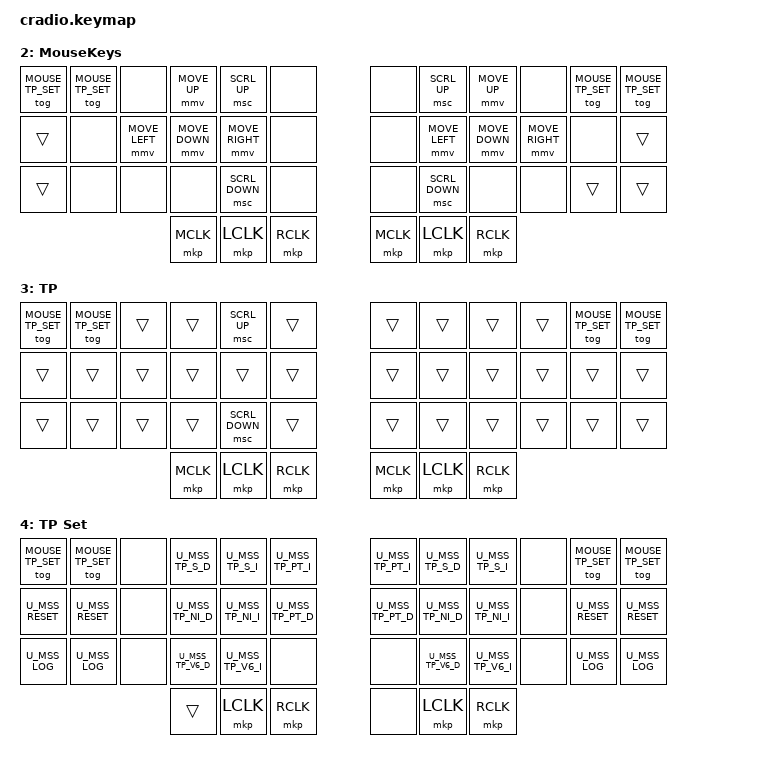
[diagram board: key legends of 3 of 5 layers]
// Copyright (c) 2022 The ZMK Contributors
// SPDX-License-Identifier: MIT

#include <behaviors.dtsi>
#include <dt-bindings/zmk/keys.h>
#include <dt-bindings/zmk/bt.h>

// Layer definitions (same as original PS/2 config)
#define BASE 0
#define LOWER 1
#define MOUSE_KEYS 2
#define MOUSE_TP 3
#define MOUSE_TP_SET 4

#define HAS_MOUSE_KEYS
#define HAS_MOUSE_TP

#ifdef HAS_MOUSE_KEYS
  #include <dt-bindings/zmk/mouse.h>
  #include <behaviors/mouse_keys.dtsi>
#endif

#ifdef HAS_MOUSE_TP
  #include <dt-bindings/zmk/mouse_settings.h>
  #include <behaviors/mouse_keys.dtsi>
  #include <behaviors/mouse_setting.dtsi>
  #include "include/mouse_tp.dtsi"
#endif

// Homery mods macro for cradio
#define HRML(k1,k2,k3,k4) &ht LSHFT k1 &ht LALT k2 &ht LCTRL k3 &ht LGUI k4
#define HRMR(k1,k2,k3,k4) &ht RGUI k1 &ht RCTRL k2 &ht RALT k3 &ht RSHFT k4

// Layer toggle helpers
#ifdef HAS_MOUSE_KEYS
  #define U_THUMB_INNER &mo MOUSE_KEYS
#else
  #define U_THUMB_INNER &none
#endif

#ifdef HAS_MOUSE_TP
  #define U_TOG_TP_SET &tog MOUSE_TP_SET
#else
  #define U_TOG_TP_SET &none
#endif

/ {
    behaviors {
        ht: hold_tap {
            compatible = "zmk,behavior-hold-tap";
            #binding-cells = <2>;
            flavor = "tap-preferred";
            tapping-term-ms = <220>;
            quick-tap-ms = <150>;
            require-prior-idle-ms = <100>;
            bindings = <&kp>, <&kp>;
        };
    };

    conditional_layers {
        compatible = "zmk,conditional-layers";
        tri_layer {
            if-layers = <1 2>;
            then-layer = <3>;
        };
    };

    keymap {
        compatible = "zmk,keymap";

        // Layer 0: Base
        default_layer {
            display-name = "Base";
            bindings = <
        //╭──────────┬──────────┬──────────┬──────────┬──────────╮   ╭──────────┬──────────┬──────────┬──────────┬──────────╮
        //│  Q       │  W       │  E       │  R       │  T       │   │  Y       │  U       │  I       │  O       │  P       │
          &kp Q &kp W &kp E &kp R    &kp T          &kp Y      &kp U    &kp I &kp O &kp P
        //├──────────┼──────────┼──────────┼──────────┼──────────┤   ├──────────┼──────────┼──────────┼──────────┼──────────┤
        //│  A       │  S       │  D       │  F       │  G       │   │  H       │  J       │  K       │  L       │ ' "      │
            &kp A &kp S &kp D &kp F     &kp G          &kp H      &kp J        &kp K        &kp L        &kp SQT
        //├──────────┼──────────┼──────────┼──────────┼──────────┤   ├──────────┼──────────┼──────────┼──────────┼──────────┤
        //│  Z       │  X       │  C       │  V       │  B       │   │  N       │  M       │ , <      │ . >      │ / ?      │
            &kp Z      &kp X      &kp C      &kp V      &kp B          &kp N      &kp M      &kp COMMA  &kp DOT    &kp FSLH
        //╰──────────┴──────────┴──────────┼──────────┼──────────┤   ├──────────┼──────────┼──────────┴──────────┴──────────╯
                                     &mo LOWER &kp SPACE U_THUMB_INNER  U_THUMB_INNER &kp RET  &mo LOWER
            >;
        };

        // Layer 1: Lower
        right_layer {
            display-name = "Lower";
            bindings = <
        //╭──────────┬──────────┬──────────┬──────────┬──────────╮   ╭──────────┬──────────┬──────────┬──────────┬──────────╮
        //│ INSERT   │  1       │  2       │  3       │          │   │ HOME     │ PAGE DN  │ PAGE UP  │ END      │  :       │
            &kp INS    &kp N1     &kp N2     &kp N3     &trans         &kp HOME   &kp PG_DN  &kp PG_UP  &kp END    &kp COLON
        //├──────────┼──────────┼──────────┼──────────┼──────────┤   ├──────────┼──────────┼──────────┼──────────┼──────────┤
        //│ DELETE   │  4       │  5       │  6       │          │   │ LEFT     │ DOWN     │ UP       │ RIGHT    │  ;       │
            &kp DEL    &kp N4     &kp N5     &kp N6     &trans         &kp LEFT   &kp DOWN   &kp UP   &kp RIGHT   &kp SEMI
        //├──────────┼──────────┼──────────┼──────────┼──────────┤   ├──────────┼──────────┼──────────┼──────────┼──────────┤
        //│ CAPS     │  7       │  8       │  9       │  0       │   │          │          │          │          │          │
           &caps_word  &kp N7     &kp N8     &kp N9     &kp N0         &trans     &trans     &trans     &trans     &trans
        //╰──────────┴──────────┴──────────┼──────────┼──────────┤   ├──────────┼──────────┼──────────┴──────────┴──────────╯
                                             &trans     &kp ESC        &trans     &trans
            >;
        };

#ifdef HAS_MOUSE_KEYS
        // Layer 2: Mouse keys
        MouseKeys_layer {
            display-name = "MouseKeys";
            bindings = <
        //╭──────────┬──────────┬──────────┬──────────┬──────────╮   ╭──────────┬──────────┬──────────┬──────────┬──────────╮
        //│  SET     │          │         UP│ SCR UP   │          │   │          │ SCR UP   │  UP      │          │  SET     │
         U_TOG_TP_SET U_TOG_TP_SET  &none    &mmv MOVE_UP &msc SCRL_UP  &none      &none  &msc SCRL_UP &mmv MOVE_UP &none  U_TOG_TP_SET U_TOG_TP_SET
        //├──────────┼──────────┼──────────┼──────────┼──────────┤   ├──────────┼──────────┼──────────┼──────────┼──────────┤
        //│          │  LFT    │  DWN    │  RGT    │          │   │          │  LFT    │  DWN    │  RGT    │          │
            &trans  &none    &mmv MOVE_LEFT &mmv MOVE_DOWN &mmv MOVE_RIGHT &none      &none &mmv MOVE_LEFT &mmv MOVE_DOWN &mmv MOVE_RIGHT &none &trans
        //├──────────┼──────────┼──────────┼──────────┼──────────┤   ├──────────┼──────────┼──────────┼──────────┼──────────┤
        //│          │          │         │  SCR DN  │          │   │          │ SCR DN   │          │          │          │
            &trans  &none    &none    &none    &msc SCRL_DOWN &none      &none &msc SCRL_DOWN &none    &none    &trans &trans
        //╰──────────┴──────────┴──────────┼──────────┼──────────┤   ├──────────┼──────────┼──────────┴──────────┴──────────╯
                                        &mkp MCLK    &mkp LCLK   &mkp RCLK      &mkp MCLK   &mkp LCLK   &mkp RCLK
            >;
        };
#endif

#ifdef HAS_MOUSE_TP
        // Layer 3: Mouse TP (auto-activated when TrackPoint moves)
        MouseTP_layer {
            display-name = "TP";
            bindings = <
        //╭──────────┬──────────┬──────────┬──────────┬──────────╮   ╭──────────┬──────────┬──────────┬──────────┬──────────╮
         U_TOG_TP_SET U_TOG_TP_SET  &trans &trans &msc SCRL_UP &trans      &trans  &trans  &trans  &trans U_TOG_TP_SET U_TOG_TP_SET
        //├──────────┼──────────┼──────────┼──────────┼──────────┤   ├──────────┼──────────┼──────────┼──────────┼──────────┤
            &trans &trans &trans &trans &trans &trans      &trans &trans &trans &trans &trans &trans
        //├──────────┼──────────┼──────────┼──────────┼──────────┤   ├──────────┼──────────┼──────────┼──────────┼──────────┤
            &trans &trans &trans &trans &msc SCRL_DOWN &trans      &trans &trans &trans &trans &trans &trans
        //╰──────────┴──────────┴──────────┼──────────┼──────────┤   ├──────────┼──────────┼──────────┴──────────┴──────────╯
                                        &mkp MCLK    &mkp LCLK   &mkp RCLK      &mkp MCLK   &mkp LCLK   &mkp RCLK
            >;
        };

        // Layer 4: Mouse TP Settings
        MouseSettings_layer {
            display-name = "TP Set";
            bindings = <
        //╭──────────┬──────────┬──────────┬──────────┬──────────╮   ╭──────────┬──────────┬──────────┬──────────┬──────────╮
         U_TOG_TP_SET U_TOG_TP_SET &none U_MSS_TP_S_D U_MSS_TP_S_I U_MSS_TP_PT_I    U_MSS_TP_PT_I U_MSS_TP_S_D U_MSS_TP_S_I &none U_TOG_TP_SET U_TOG_TP_SET
        //├──────────┼──────────┼──────────┼──────────┼──────────┤   ├──────────┼──────────┼──────────┼──────────┼──────────┤
         U_MSS_RESET   U_MSS_RESET   &none U_MSS_TP_NI_D U_MSS_TP_NI_I U_MSS_TP_PT_D    U_MSS_TP_PT_D U_MSS_TP_NI_D U_MSS_TP_NI_I &none U_MSS_RESET U_MSS_RESET
        //├──────────┼──────────┼──────────┼──────────┼──────────┤   ├──────────┼──────────┼──────────┼──────────┼──────────┤
           U_MSS_LOG    U_MSS_LOG    &none U_MSS_TP_V6_D U_MSS_TP_V6_I &none         &none  U_MSS_TP_V6_D U_MSS_TP_V6_I &none  U_MSS_LOG  U_MSS_LOG
        //╰──────────┴──────────┴──────────┼──────────┼──────────┤   ├──────────┼──────────┼──────────┴──────────┴──────────╯
                                        &trans     &mkp LCLK    &mkp RCLK        &none    &mkp LCLK   &mkp RCLK
            >;
        };
#endif
    };
};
